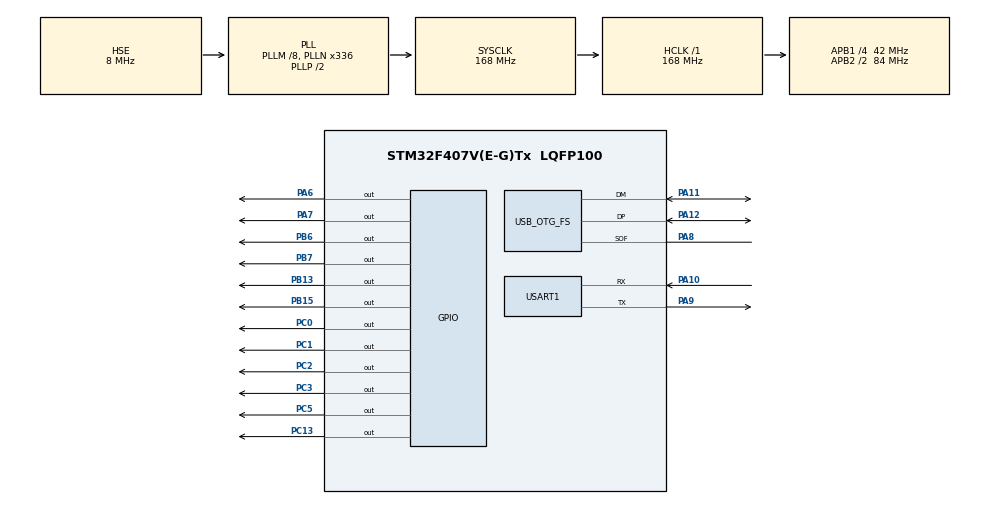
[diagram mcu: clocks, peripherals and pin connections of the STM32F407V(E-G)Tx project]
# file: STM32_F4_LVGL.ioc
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Mcu.Family=STM32F4
Mcu.Name=STM32F407V(E-G)Tx
Mcu.Package=LQFP100
NVIC.PriorityGroup=NVIC_PRIORITYGROUP_4
PA10.Mode=Asynchronous
PA10.Signal=USART1_RX
PA11.Mode=Device_Only
PA11.Signal=USB_OTG_FS_DM
PA12.Mode=Device_Only
PA12.Signal=USB_OTG_FS_DP
PA13.Mode=Serial_Wire
PA13.Signal=SYS_JTMS-SWDIO
PA14.Mode=Serial_Wire
PA14.Signal=SYS_JTCK-SWCLK
PA6.Signal=GPIO_Output
PA7.Signal=GPIO_Output
PA8.Mode=Activate_SOF_FS
PA8.Signal=USB_OTG_FS_SOF
PA9.Mode=Asynchronous
PA9.Signal=USART1_TX
PB13.Signal=GPIO_Output
PB15.Signal=GPIO_Output
PB6.Signal=GPIO_Output
PB7.Signal=GPIO_Output
PC0.Signal=GPIO_Output
PC1.Signal=GPIO_Output
PC13-ANTI_TAMP.Signal=GPIO_Output
PC2.Signal=GPIO_Output
PC3.Signal=GPIO_Output
PC5.Signal=GPIO_Output
PH0-OSC_IN.Mode=HSE-External-Oscillator
PH0-OSC_IN.Signal=RCC_OSC_IN
PH1-OSC_OUT.Mode=HSE-External-Oscillator
PH1-OSC_OUT.Signal=RCC_OSC_OUT
ProjectManager.HeapSize=0x2000
ProjectManager.StackSize=0x4000
ProjectManager.TargetToolchain=STM32CubeIDE
RCC.48MHZClocksFreq_Value=48000000
RCC.AHBFreq_Value=168000000
RCC.APB1CLKDivider=RCC_HCLK_DIV4
RCC.APB1Freq_Value=42000000
RCC.APB1TimFreq_Value=84000000
RCC.APB2CLKDivider=RCC_HCLK_DIV2
RCC.APB2Freq_Value=84000000
RCC.APB2TimFreq_Value=168000000
RCC.CortexFreq_Value=168000000
RCC.HCLKFreq_Value=168000000
RCC.HSE_VALUE=8000000
RCC.HSI_VALUE=16000000
RCC.LSE_VALUE=32768
RCC.PLLM=8
RCC.PLLN=336
RCC.PLLQ=7
RCC.SYSCLKFreq_VALUE=168000000
RCC.SYSCLKSource=RCC_SYSCLKSOURCE_PLLCLK
RCC.VCOOutputFreq_Value=336000000
USART1.VirtualMode=VM_ASYNC
USB_OTG_FS.VirtualMode=Device_Only
board=custom

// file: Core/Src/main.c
/* USER CODE BEGIN Header */
/**
  ******************************************************************************
  * @file           : main.c
  * @brief          : Main program body
  ******************************************************************************
  * @attention
  *
  * Copyright (c) 2024 STMicroelectronics.
  * All rights reserved.
  *
  * This software is licensed under terms that can be found in the LICENSE file
  * in the root directory of this software component.
  * If no LICENSE file comes with this software, it is provided AS-IS.
  *
  ******************************************************************************
  */
/* USER CODE END Header */
#include "main.h"

/* USER CODE BEGIN Includes */

#include "../../Drivers/lvgl/src/lv_init.h"
#include "../../Drivers/lvgl/src/lvgl.h"
#include "../../Drivers/lvgl/examples/porting/lv_port_disp.h"
#include "../../Drivers/lvgl/demos/scroll/lv_demo_scroll.h"
/* USER CODE END Includes */

UART_HandleTypeDef huart1;

PCD_HandleTypeDef hpcd_USB_OTG_FS;

void SystemClock_Config(void);
static void MX_GPIO_Init(void);
static void MX_USART1_UART_Init(void);
static void MX_USB_OTG_FS_PCD_Init(void);

int main(void)
{

  /* MCU Configuration--------------------------------------------------------*/

  /* Reset of all peripherals, Initializes the Flash interface and the Systick. */
  HAL_Init();

  /* Configure the system clock */
  SystemClock_Config();

  /* Initialize all configured peripherals */
  MX_GPIO_Init();
  MX_USART1_UART_Init();
  MX_USB_OTG_FS_PCD_Init();
    HAL_GPIO_WritePin(GPIOC, GPIO_PIN_13, GPIO_PIN_RESET);
    HAL_GPIO_WritePin(GPIOA, GPIO_PIN_6, GPIO_PIN_RESET);
    HAL_GPIO_WritePin(GPIOA, GPIO_PIN_7, GPIO_PIN_RESET);
  /* USER CODE BEGIN 2 */
    HAL_PCD_DeInit(&hpcd_USB_OTG_FS);

    lv_init();
    HAL_UART_Transmit(&huart1, (uint8_t *)"LCD START\n", 10, 100);

    /* LVGL 显示接口初始化（内含 LCD_Init + display create + flush_cb + buffer） */
    lv_port_disp_init();

    /* 设置背景色并启动 scroll demo */
    lv_obj_set_style_bg_color(lv_screen_active(), lv_color_hex(0x003888), LV_PART_MAIN);
    lv_demo_scroll();

    /* USER CODE END 2 */

  /* Infinite loop */
  /* USER CODE BEGIN WHILE */
  while (1)
  {
      lv_task_handler();
      HAL_UART_Transmit(&huart1, (uint8_t *)"ONE TIME\n", 9, 100);
    /* USER CODE END WHILE */

  }
}

void SystemClock_Config(void)
{
  RCC_OscInitTypeDef RCC_OscInitStruct = {0};
  RCC_ClkInitTypeDef RCC_ClkInitStruct = {0};

  /** Configure the main internal regulator output voltage
  */
  __HAL_RCC_PWR_CLK_ENABLE();
  __HAL_PWR_VOLTAGESCALING_CONFIG(PWR_REGULATOR_VOLTAGE_SCALE1);

  /** Initializes the RCC Oscillators according to the specified parameters
  * in the RCC_OscInitTypeDef structure.
  */
  RCC_OscInitStruct.OscillatorType = RCC_OSCILLATORTYPE_HSE;
  RCC_OscInitStruct.HSEState = RCC_HSE_ON;
  RCC_OscInitStruct.PLL.PLLState = RCC_PLL_ON;
  RCC_OscInitStruct.PLL.PLLSource = RCC_PLLSOURCE_HSE;
  RCC_OscInitStruct.PLL.PLLM = 8;
  RCC_OscInitStruct.PLL.PLLN = 336;
  RCC_OscInitStruct.PLL.PLLP = RCC_PLLP_DIV2;
  RCC_OscInitStruct.PLL.PLLQ = 7;
  if (HAL_RCC_OscConfig(&RCC_OscInitStruct) != HAL_OK)
  {
    Error_Handler();
  }

  /** Initializes the CPU, AHB and APB buses clocks
  */
  RCC_ClkInitStruct.ClockType = RCC_CLOCKTYPE_HCLK|RCC_CLOCKTYPE_SYSCLK
                              |RCC_CLOCKTYPE_PCLK1|RCC_CLOCKTYPE_PCLK2;
  RCC_ClkInitStruct.SYSCLKSource = RCC_SYSCLKSOURCE_PLLCLK;
  RCC_ClkInitStruct.AHBCLKDivider = RCC_SYSCLK_DIV1;
  RCC_ClkInitStruct.APB1CLKDivider = RCC_HCLK_DIV4;
  RCC_ClkInitStruct.APB2CLKDivider = RCC_HCLK_DIV2;

  if (HAL_RCC_ClockConfig(&RCC_ClkInitStruct, FLASH_LATENCY_5) != HAL_OK)
  {
    Error_Handler();
  }
}

static void MX_USART1_UART_Init(void)
{

  huart1.Instance = USART1;
  huart1.Init.BaudRate = 115200;
  huart1.Init.WordLength = UART_WORDLENGTH_8B;
  huart1.Init.StopBits = UART_STOPBITS_1;
  huart1.Init.Parity = UART_PARITY_NONE;
  huart1.Init.Mode = UART_MODE_TX_RX;
  huart1.Init.HwFlowCtl = UART_HWCONTROL_NONE;
  huart1.Init.OverSampling = UART_OVERSAMPLING_16;
  if (HAL_UART_Init(&huart1) != HAL_OK)
  {
    Error_Handler();
  }

}

static void MX_USB_OTG_FS_PCD_Init(void)
{

  hpcd_USB_OTG_FS.Instance = USB_OTG_FS;
  hpcd_USB_OTG_FS.Init.dev_endpoints = 4;
  hpcd_USB_OTG_FS.Init.speed = PCD_SPEED_FULL;
  hpcd_USB_OTG_FS.Init.dma_enable = DISABLE;
  hpcd_USB_OTG_FS.Init.phy_itface = PCD_PHY_EMBEDDED;
  hpcd_USB_OTG_FS.Init.Sof_enable = ENABLE;
  hpcd_USB_OTG_FS.Init.low_power_enable = DISABLE;
  hpcd_USB_OTG_FS.Init.lpm_enable = DISABLE;
  hpcd_USB_OTG_FS.Init.vbus_sensing_enable = DISABLE;
  hpcd_USB_OTG_FS.Init.use_dedicated_ep1 = DISABLE;
  if (HAL_PCD_Init(&hpcd_USB_OTG_FS) != HAL_OK)
  {
    Error_Handler();
  }

}

static void MX_GPIO_Init(void)
{
  GPIO_InitTypeDef GPIO_InitStruct = {0};

  /* GPIO Ports Clock Enable */
  __HAL_RCC_GPIOC_CLK_ENABLE();
  __HAL_RCC_GPIOH_CLK_ENABLE();
  __HAL_RCC_GPIOA_CLK_ENABLE();
  __HAL_RCC_GPIOB_CLK_ENABLE();

  /*Configure GPIO pin Output Level */
  HAL_GPIO_WritePin(GPIOC, GPIO_PIN_13|GPIO_PIN_0|GPIO_PIN_1|GPIO_PIN_2
                          |GPIO_PIN_3|GPIO_PIN_5, GPIO_PIN_RESET);

  /*Configure GPIO pin Output Level */
  HAL_GPIO_WritePin(GPIOA, GPIO_PIN_6|GPIO_PIN_7, GPIO_PIN_RESET);

  /*Configure GPIO pin Output Level */
  HAL_GPIO_WritePin(GPIOB, GPIO_PIN_13|GPIO_PIN_15|GPIO_PIN_6|GPIO_PIN_7, GPIO_PIN_RESET);

  /*Configure GPIO pins : PC13 PC0 PC1 PC2
                           PC3 PC5 */
  GPIO_InitStruct.Pin = GPIO_PIN_13|GPIO_PIN_0|GPIO_PIN_1|GPIO_PIN_2
                          |GPIO_PIN_3|GPIO_PIN_5;
  GPIO_InitStruct.Mode = GPIO_MODE_OUTPUT_PP;
  GPIO_InitStruct.Pull = GPIO_NOPULL;
  GPIO_InitStruct.Speed = GPIO_SPEED_FREQ_LOW;
  HAL_GPIO_Init(GPIOC, &GPIO_InitStruct);

  /*Configure GPIO pins : PA6 PA7 */
  GPIO_InitStruct.Pin = GPIO_PIN_6|GPIO_PIN_7;
  GPIO_InitStruct.Mode = GPIO_MODE_OUTPUT_PP;
  GPIO_InitStruct.Pull = GPIO_NOPULL;
  GPIO_InitStruct.Speed = GPIO_SPEED_FREQ_LOW;
  HAL_GPIO_Init(GPIOA, &GPIO_InitStruct);

  /*Configure GPIO pins : PB13 PB15 PB6 PB7 */
  GPIO_InitStruct.Pin = GPIO_PIN_13|GPIO_PIN_15|GPIO_PIN_6|GPIO_PIN_7;
  GPIO_InitStruct.Mode = GPIO_MODE_OUTPUT_PP;
  GPIO_InitStruct.Pull = GPIO_NOPULL;
  GPIO_InitStruct.Speed = GPIO_SPEED_FREQ_LOW;
  HAL_GPIO_Init(GPIOB, &GPIO_InitStruct);

}

void Error_Handler(void)
{
  __disable_irq();
  while (1)
  {
  }
}
